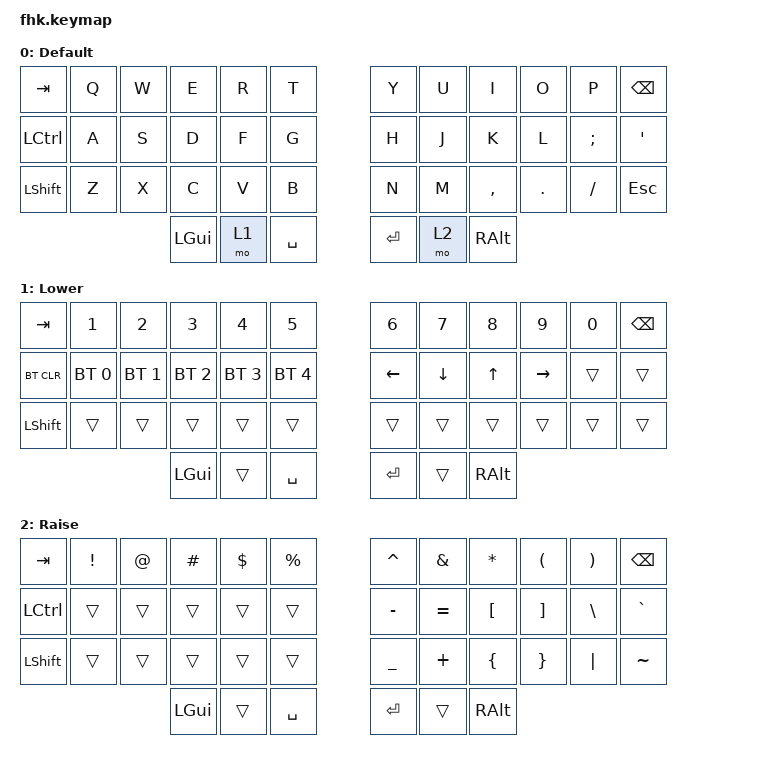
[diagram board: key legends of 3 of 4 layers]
#define ZMK_POINTING_DEFAULT_MOVE_VAL 1200  // 600
#define ZMK_POINTING_DEFAULT_SCRL_VAL 25   // 10

#include <input/processors.dtsi>
#include <zephyr/dt-bindings/input/input-event-codes.h>
#include <behaviors.dtsi>
#include <dt-bindings/zmk/bt.h>
#include <dt-bindings/zmk/keys.h>
#include <dt-bindings/zmk/outputs.h>
#include <dt-bindings/zmk/pointing.h>

&mmv_input_listener { input-processors = <&zip_xy_scaler 2 1>; };

&msc_input_listener { input-processors = <&zip_scroll_scaler 2 1>; };

&msc {
    acceleration-exponent = <1>;      // 0
    time-to-max-speed-ms = <100>;       // 300
    delay-ms = <0>;                   // 0
};

&mmv {
    time-to-max-speed-ms = <500>;
    acceleration-exponent = <1>;
    trigger-period-ms = <16>;
};

&soft_off { hold-time-ms = <2000>; };

/ {
    behaviors {
        td0: td0 {
            compatible = "zmk,behavior-tap-dance";
            #binding-cells = <0>;
            bindings = <&kp LEFT_SHIFT>, <&kp CAPS>;
        };
    };

    combos {
        compatible = "zmk,combos";

        softoff {
            bindings = <&soft_off>;
            key-positions = <1 15 29>;
        };
    };
    
    keymap {
        compatible = "zmk,keymap";

        default_layer {
                display-name = "Default";
                bindings = <
   &kp TAB   &kp Q &kp W &kp E &kp R &kp T   &kp Y &kp U  &kp I     &kp O   &kp P    &kp BSPC
   &kp LCTRL &kp A &kp S &kp D &kp F &kp G   &kp H &kp J  &kp K     &kp L   &kp SEMI &kp SQT
   &kp LSHFT &kp Z &kp X &kp C &kp V &kp B   &kp N &kp M  &kp COMMA &kp DOT &kp FSLH &kp ESC
                  &kp LGUI &mo 1 &kp SPACE   &kp RET &mo 2 &kp RALT
                        >;
                };

        lower_layer {
                display-name = "Lower";
                bindings = <
   &kp TAB    &kp N1       &kp N2       &kp N3       &kp N4       &kp N5         &kp N6   &kp N7   &kp N8 &kp N9    &kp N0 &kp BSPC
   &bt BT_CLR &bt BT_SEL 0 &bt BT_SEL 1 &bt BT_SEL 2 &bt BT_SEL 3 &bt BT_SEL 4   &kp LEFT &kp DOWN &kp UP &kp RIGHT &trans &trans
   &kp LSHFT  &trans       &trans       &trans       &trans       &trans         &trans   &trans   &trans &trans    &trans &trans
                                        &kp LGUI     &trans       &kp SPACE      &kp RET  &trans   &kp RALT
                        >;
                };

        raise_layer {
                display-name = "Raise";
                bindings = <
   &kp  TAB  &kp EXCL &kp AT &kp HASH &kp DLLR &kp PRCNT   &kp CARET &kp AMPS  &kp ASTRK &kp LPAR &kp RPAR &kp BSPC
   &kp LCTRL &trans   &trans &trans   &trans   &trans      &kp MINUS &kp EQUAL &kp LBKT  &kp RBKT &kp BSLH &kp GRAVE
   &kp LSHFT &trans   &trans &trans   &trans   &trans      &kp UNDER &kp PLUS  &kp LBRC  &kp RBRC &kp PIPE &kp TILDE
                             &kp LGUI &trans   &kp SPACE   &kp RET   &trans    &kp RALT
                        >;
                };

        Fn_layer {
                display-name = "Fn";
                bindings = <
    &trans  &kp F1      &kp F2      &kp F3       &kp F4     &kp F5                 &kp F6       &kp F7     &kp F8       &kp F9      &kp F10          &kp F11
    &trans  &trans      &mkp LCLK   &mkp MCLK    &mkp RCLK  &mkp MB4               &bootloader  &mkp LCLK  &mkp MCLK    &mkp RCLK   &kp PRINTSCREEN  &kp F12
    &trans  &sys_reset  &trans      &bootloader  &trans     &mkp MB5 &kp C_MUTE    &trans       &trans     &bootloader  &sys_reset  &kp SCROLLLOCK   &kp PAUSE_BREAK
                                    &trans       &trans     &trans                 &trans       &trans     &trans
                        >;
                }; 
        };
};
